# RE01_256KB register map
Vendor: Renesas Electronics Corporation; Series: RE01; File version: 1.00.01
CPU: CM0PLUS r0p1, little endian, MPU, no FPU, VTOR, 2 interrupt priority bits, 32 interrupts
Registers are 8-bit, read-write, reset 0x0 unless marked. A register's access mark holds for its fields unless they carry their own. Offsets are from the block's base; [hi:lo] are bit positions; {n}, {i} and the like mark numbered series; 'fields as' and 'values as' point back to an identical list.

## GDT — 2D Graphics Data Conversion Circuit
Base 0x40070800
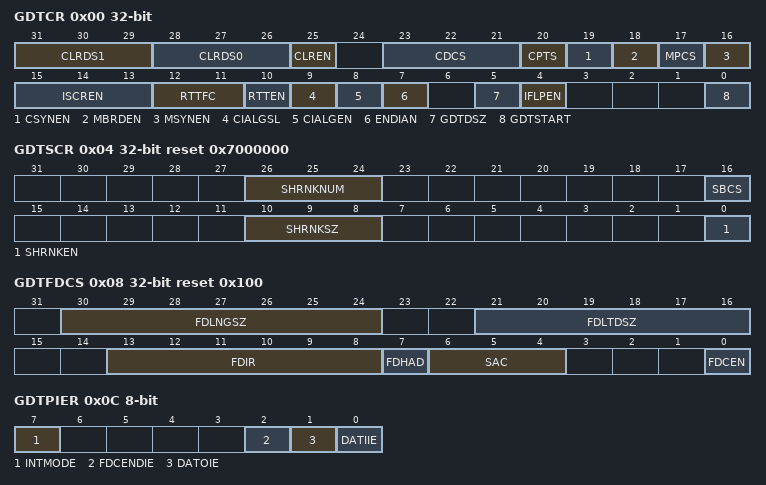
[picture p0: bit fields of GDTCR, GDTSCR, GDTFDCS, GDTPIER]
0x00 GDTCR 32-bit — GDT Control Register
  [31:29] CLRDS1 — 1 Data Color Setting
  [28:26] CLRDS0 — 0 Data Color Setting
  [25] CLREN — Image Colorization Function Enable
    0=Colorization of the image is disabled; 1=Colorization of the image is enabled
  [23:21] CDCS — Specified Color Setting
  [20] CPTS — Color Image Priority/Transparency Setting
    0=The specified color of the foreground on the forefront is displayed (priority color mode); 1=The same color as the background color in the parts of the foreground image with the specified color is displayed (transparent color mode)
  [19] CSYNEN — Color Image Compositing Enable
    0=The compositing of color images is disabled; 1=The compositing of color images is enabled
  [18] MBRDEN — Image Trimming Enable
    0=Image trimming is disabled; 1=Image trimming is enabled
  [17] MPCS — Monochrome Priority Color Setting
    0=Priority in compositing is given to pixels having the value 1 in the foreground image data; 1=Priority in compositing is given to pixels having the value 0 in the foreground image data
  [16] MSYNEN — Monochrome Image Compositing Enable
    0=The compositing of monochrome images is disabled; 1=The compositing of monochrome images is enabled
  [15:13] ISCREN — Image Scrolling Enable
    0=Image scrolling is disabled; 1=The image is displayed after right-shifting by 1 bit; {v}=The image is displayed after right-shifting by {v} bits (v=2..7)
  [12:11] RTTFC — Rotation Type Select
    0=90-degree clockwise; 1=90-degree counterclockwise; 2=Vertical flip; 3=Horizontal flip
  [10] RTTEN — Rotation Enable
    0=Rotation is disabled; 1=Rotation is enabled
  [9] CIALGSL — Color Data Sorting Select
    0=The color data are sorted in order of R, G, and B represented by three bits; 1=The color data are sorted in order of R, G, and B represented by three bits, with one bit of padding, for a total of four bits
  [8] CIALGEN — Color Data Sorting Enable
    0=The sorting of color data is disabled; 1=The sorting of color data is enabled
  [7] ENDIAN — Endian Conversion
    0=Endian conversion is disabled; 1=Endian conversion is enabled
  [5] GDTDSZ — Image Processing Data Size Select
    0=The processable data size is 16 × 16 bits; 1=The processable data size is 8 × 8 bits
  [4] IFLPEN — Inversion Enable
    0=Bit inversion is disabled; 1=Bit inversion is enabled
  [0] GDTSTART — GDT Processing Start
    0=GDT is stopped; 1=GDT processing is started
0x04 GDTSCR 32-bit reset 0x7000000 — Reduction Function Control Register
  [26:24] SHRNKNUM — Number of Images for Scaling Down
    {v}={v+1} (v=0..7)
  [16] SBCS — Unused Background Color Setting
    0=0 is written to the unused bits after scaling down; 1=1 is written to the unused bits after scaling down
  [10:8] SHRNKSZ — Scaling Down Ratio Select
    {v}=Images are scaled down to {v+1}/8 by pixel averaging (v=0..6); 7=Images are scaled down to 1/2 by pixel averaging
  [0] SHRNKEN — Scaling Down Enable
    0=Scaling down is disabled; 1=Scaling down is enabled
0x08 GDTFDCS 32-bit reset 0x100 — Glyph Data Image Conversion Setting Register
  [30:24] FDLNGSZ — Glyph Data Vertical Size Setting
  [21:16] FDLTDSZ — Glyph Data Horizontal Size Setting
  [13:8] FDIR — Number of Rounds of Data Processing Setting
  [7] FDHAD — Unused Bit Setting
    0=0 is written to the unused bits after glyph conversion; 1=1 is written to the unused bits after glyph conversion
  [6:4] SAC — Start Address Change
    0=No shifting; 1=Right-shifted by 1 bit; {v}=Right-shifted by {v} bits (v=2..7)
  [0] FDCEN — Glyph Data Conversion Enable
    0=Conversion of glyph data into image data is disabled; 1=Conversion of glyph data into image data is enabled
0x0C GDTPIER — Image Data Processing Interrupt Enable Register
  [7] INTMODE — GDT Interrupt Mode Select
    0=Selects the conveying of interrupt signals to the DMAC; 1=Selects the conveying of interrupt signals to the DTC
  [2] FDCENDIE — Glyph Data Conversion Complete Interrupt Enable
    0=Interrupt requests are disabled; 1=Interrupt requests are enabled
  [1] DATOIE — Image Data Output Request Interrupt Enable
    values as FDCENDIE
  [0] DATIIE — Image Data Input Request Interrupt Enable
    values as FDCENDIE
{0x100+4i} GDTIBUF{i} (i=0..47) 32-bit wo — GDT Image Data Input Register
{0x200+4i} GDTOBUF{i} (i=0..31) 32-bit ro — GDT Image Data Output Register
